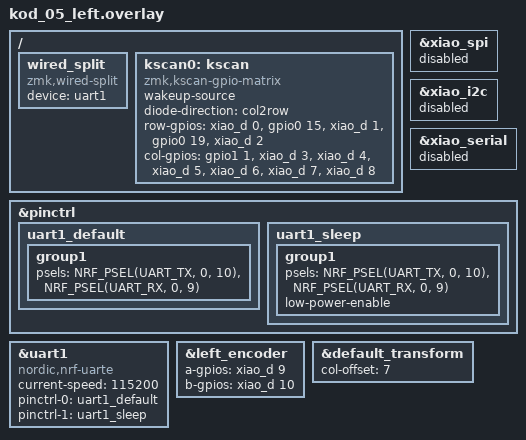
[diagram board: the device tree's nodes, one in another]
/*
 * Copyright (c) 2024 kodomari
 * SPDX-License-Identifier: MIT
 */
#include "kod_05.dtsi"
#include <zephyr/dt-bindings/pinctrl/nrf-pinctrl.h>

&xiao_spi { status = "disabled"; };
&xiao_i2c { status = "disabled"; };
&xiao_serial { status = "disabled"; };

/*
 * 左右リンク(ヒンジ跨ぎ, wired split): PD_1=RX1(P0.09) / PD_2=TX1(P0.10)
 * 左手はperipheral側。CONFIG_ZMK_SPLIT_ROLE_CENTRAL は未設定(=n)。
 */
&pinctrl {
    uart1_default: uart1_default {
        group1 {
            psels = <NRF_PSEL(UART_TX, 0, 10)>,
                    <NRF_PSEL(UART_RX, 0, 9)>;
        };
    };

    uart1_sleep: uart1_sleep {
        group1 {
            psels = <NRF_PSEL(UART_TX, 0, 10)>,
                    <NRF_PSEL(UART_RX, 0, 9)>;
            low-power-enable;
        };
    };
};

&uart1 {
    compatible = "nordic,nrf-uarte";
    status = "okay";
    current-speed = <115200>;
    pinctrl-0 = <&uart1_default>;
    pinctrl-1 = <&uart1_sleep>;
    pinctrl-names = "default", "sleep";
};

/ {
    wired_split: wired_split {
        compatible = "zmk,wired-split";
        device = <&uart1>;
    };
};

/*
 * kod-05 アダプタ(左手用)FFC1 ピン割当 (実測確認済み 2026-08):
 *   15:ROW0=D0(P0.02)  13:ROW1=D1(P0.03)  11:ROW2=D2(P0.28)
 *    9:ROW3=D3(P0.29)   8:ROW4=D4(P0.04)
 *    7:COL0=D5(P0.05)   6:COL1=D6(P1.11)   5:COL2=D7(P1.12)
 *    4:COL3=D8(P1.13)   3:COL4=D9(P1.14)   2:COL5=D10(P1.15)
 *   14:COL6=拡張ピン P0.15
 *    1:GND(J1へ別線)
 *   12:ENC_A=拡張ピン P0.19   10:ENC_B=拡張ピン P1.01
 */
/ {
    kscan0: kscan {
        compatible = "zmk,kscan-gpio-matrix";
        wakeup-source;
        diode-direction = "col2row";

row-gpios
          = <&xiao_d 0  (GPIO_ACTIVE_HIGH | GPIO_PULL_DOWN)>   /* ROW0 = adapter pad15 */
          , <&gpio0 15  (GPIO_ACTIVE_HIGH | GPIO_PULL_DOWN)>   /* ROW1 = adapter pad14 = P0.15 */
          , <&xiao_d 1  (GPIO_ACTIVE_HIGH | GPIO_PULL_DOWN)>   /* ROW2 = adapter pad13 */
          , <&gpio0 19  (GPIO_ACTIVE_HIGH | GPIO_PULL_DOWN)>   /* ROW3 = adapter pad12 = P0.19 */
          , <&xiao_d 2  (GPIO_ACTIVE_HIGH | GPIO_PULL_DOWN)>   /* ROW4 = adapter pad11 */
          ;

        col-gpios
          = <&gpio1 1   GPIO_ACTIVE_HIGH>   /* COL0 = adapter pad10 = P1.01 */
          , <&xiao_d 3  GPIO_ACTIVE_HIGH>   /* COL1 = adapter pad9 */
          , <&xiao_d 4  GPIO_ACTIVE_HIGH>   /* COL2 = adapter pad8 */
          , <&xiao_d 5  GPIO_ACTIVE_HIGH>   /* COL3 = adapter pad7 */
          , <&xiao_d 6  GPIO_ACTIVE_HIGH>   /* COL4 = adapter pad6 */
          , <&xiao_d 7  GPIO_ACTIVE_HIGH>   /* COL5 = adapter pad5 */
          , <&xiao_d 8  GPIO_ACTIVE_HIGH>   /* COL6 = adapter pad4 */
          ;
    };
};

&left_encoder {
    status = "okay";
    a-gpios = <&xiao_d 9  (GPIO_ACTIVE_HIGH | GPIO_PULL_UP)>;
    b-gpios = <&xiao_d 10 (GPIO_ACTIVE_HIGH | GPIO_PULL_UP)>;
};

&default_transform {
    /* peripheral(左手)側。centralの列数(7)ぶんオフセットする */
    col-offset = <7>;
};
